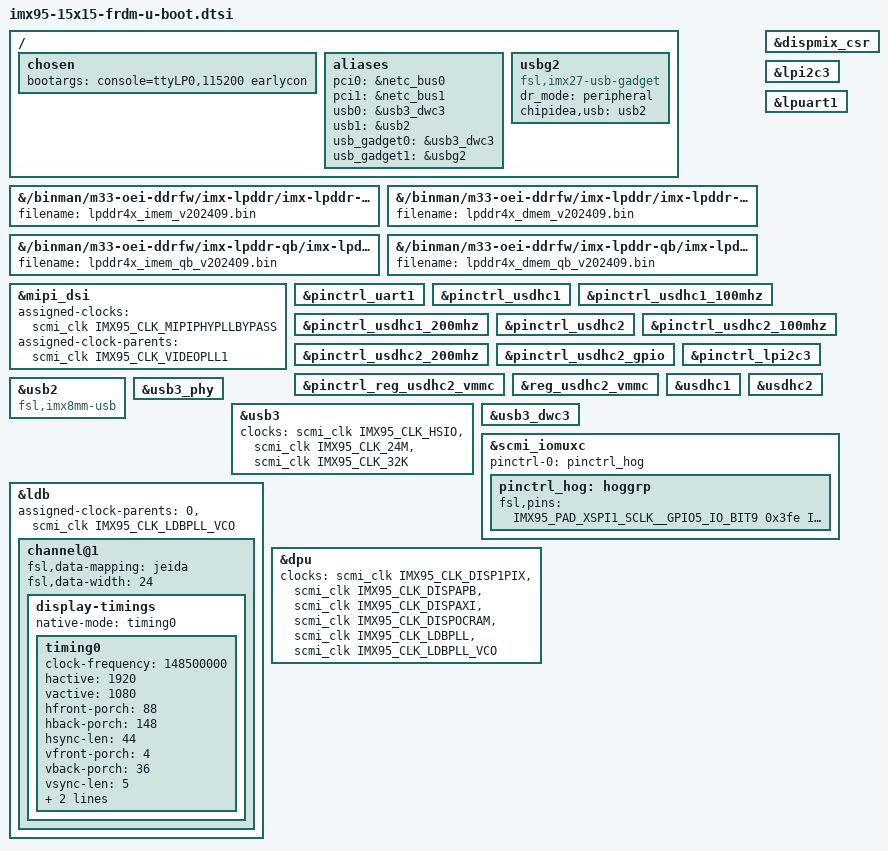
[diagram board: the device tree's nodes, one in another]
// SPDX-License-Identifier: GPL-2.0+
/*
 * Copyright 2025 NXP
 */

/ {
	chosen {
		bootargs = "console=ttyLP0,115200 earlycon";
	};

	aliases {
		pci0 = &netc_bus0;
		pci1 = &netc_bus1;
		usb0 = &usb3_dwc3;
		usb1 = &usb2;
		usb_gadget0 = &usb3_dwc3;
		usb_gadget1 = &usbg2;
	};

	usbg2: usbg2 {
		compatible = "fsl,imx27-usb-gadget";
		dr_mode = "peripheral";
		chipidea,usb = <&usb2>;
		bootph-pre-ram;
		status = "okay";
	};
};

&{/binman/m33-oei-ddrfw/imx-lpddr/imx-lpddr-imem} {
	filename = "lpddr4x_imem_v202409.bin";
};

&{/binman/m33-oei-ddrfw/imx-lpddr/imx-lpddr-dmem} {
	filename = "lpddr4x_dmem_v202409.bin";
};

&{/binman/m33-oei-ddrfw/imx-lpddr-qb/imx-lpddr-imem-qb} {
	filename = "lpddr4x_imem_qb_v202409.bin";
};

&{/binman/m33-oei-ddrfw/imx-lpddr-qb/imx-lpddr-dmem-qb} {
	filename = "lpddr4x_dmem_qb_v202409.bin";
};

&dispmix_csr {
	/delete-property/ assigned-clocks;
	/delete-property/ assigned-clock-rates;
	/delete-property/ assigned-clock-parents;
};

&lpi2c3 {
	bootph-some-ram;
};

&lpuart1 {
	bootph-pre-ram;
};

&mipi_dsi {
	assigned-clocks = <&scmi_clk IMX95_CLK_MIPIPHYPLLBYPASS>;
	assigned-clock-parents = <&scmi_clk IMX95_CLK_VIDEOPLL1>;
};

&pinctrl_uart1 {
	bootph-pre-ram;
};

&pinctrl_usdhc1 {
	bootph-pre-ram;
};

&pinctrl_usdhc1_100mhz {
	bootph-pre-ram;
};

&pinctrl_usdhc1_200mhz {
	bootph-pre-ram;
};

&pinctrl_usdhc2 {
	bootph-pre-ram;
};

&pinctrl_usdhc2_100mhz {
	bootph-pre-ram;
};

&pinctrl_usdhc2_200mhz {
	bootph-pre-ram;
};

&pinctrl_usdhc2_gpio {
	bootph-pre-ram;
};

&pinctrl_reg_usdhc2_vmmc {
	bootph-pre-ram;
};

&pinctrl_lpi2c3 {
	bootph-some-ram;
};

&reg_usdhc2_vmmc {
	bootph-pre-ram;
};

&usdhc1 {
	bootph-pre-ram;
};

&usdhc2 {
	bootph-pre-ram;
};

&usb2 {
	compatible = "fsl,imx8mm-usb", "fsl,imx7d-usb";
	/delete-property/power-domains;
	bootph-pre-ram;
};

&usb3_phy {
	bootph-pre-ram;
};

&usb3 {
	clocks = <&scmi_clk IMX95_CLK_HSIO>,
			 <&scmi_clk IMX95_CLK_24M>,
			 <&scmi_clk IMX95_CLK_32K>;
	clock-names = "hsio", "ref", "suspend";

	/delete-property/power-domains;
	bootph-pre-ram;
};

&usb3_dwc3 {
	bootph-pre-ram;
};

&scmi_iomuxc {
	pinctrl-names = "default";
	pinctrl-0 = <&pinctrl_hog>;

	pinctrl_hog: hoggrp {
		bootph-all;
		bootph-pre-ram;

		fsl,pins = <
			IMX95_PAD_XSPI1_SCLK__GPIO5_IO_BIT9			0x3fe
			IMX95_PAD_CCM_CLKO1__GPIO3_IO_BIT26			0x3fe
			IMX95_PAD_CCM_CLKO2__GPIO3_IO_BIT27			0x3fe
		>;
	};
};

&ldb {
	assigned-clock-parents = <0>,
			  <&scmi_clk IMX95_CLK_LDBPLL_VCO>;

	channel@1 {
		fsl,data-mapping = "jeida";
		fsl,data-width = <24>;

		display-timings {
			native-mode = <&timing0>;

			timing0: timing0 {
				clock-frequency = <148500000>;
				hactive = <1920>;
				vactive = <1080>;
				hfront-porch = <88>;
				hback-porch = <148>;
				hsync-len = <44>;
				vfront-porch = <4>;
				vback-porch = <36>;
				vsync-len = <5>;
				hsync-active = <1>;
				vsync-active = <1>;
			};
		};
	};
};

&dpu {
	clocks = <&scmi_clk IMX95_CLK_DISP1PIX>,
				 <&scmi_clk IMX95_CLK_DISPAPB>,
				 <&scmi_clk IMX95_CLK_DISPAXI>,
				 <&scmi_clk IMX95_CLK_DISPOCRAM>,
				 <&scmi_clk IMX95_CLK_LDBPLL>,
				 <&scmi_clk IMX95_CLK_LDBPLL_VCO>;
};
